# MLB0_VBP2APB_WRAP_MLB_CFG_VBP_MLBDIM register map
Vendor: Texas Instruments
Peripheral module from a debugger description file (folder J7ES).
Registers are 32-bit, read-write, reset 0x0 unless marked. A register's access mark holds for its fields unless they carry their own. Offsets are as the file gives them; lines under a group give offsets from that group; [hi:lo] are bit positions; {n}, {i} and the like mark numbered series; 'fields as' and 'values as' point back to an identical list; <NAME> marks a mode.

## MLB0_VBP2APB_WRAP_MLB_CFG_VBP_MLBDIM
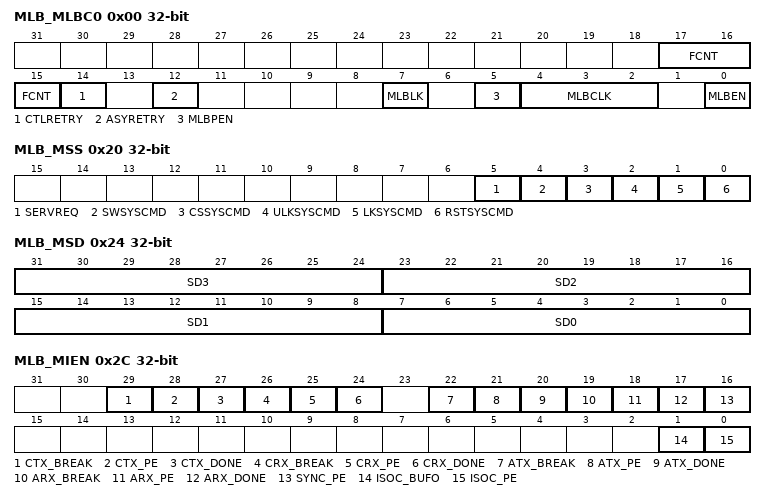
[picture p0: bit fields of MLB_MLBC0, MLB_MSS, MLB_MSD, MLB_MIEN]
0x00 MLB_MLBC0 access per field — MediaLB Control 0 Register.
  [17:15] FCNT rw — Number of frames per sub-buffer (synchronous channels).
  [14] CTLRETRY rw — Control Tx packet retry. When set, a control packet that is flagged with a Break or ProtocolError by the receiver is retransmitted. When cleared, a control packet that is flagged with a Break or ProtocolError by the receiver is skipped.
  [12] ASYRETRY rw — Asynchronous Tx packet retry. Asynchronous Tx packet retry. When set, an asynchronous packet that is flagged with a Break or ProtocolError by the receiver is retransmitted. When cleared, an asynchronous packet that is flagged with a Break or ProtocolError by the receiver is skipped.
  [7] MLBLK ro — MediaLB lock status. When set, indicates that the MediaLB block is synchronized to the incoming MediaLB frame. If MLBLK is clear (unlocked), MLBLK is set after FRAMESYNC is detected at the same position for three consecutive frames. If MLBLK is set (locked), MLBLK is cleared after not receiving FRAMESYNC at the expected time for two consecutive frames. While MLBLK is set, FRAMESYNC patterns occurring at locations other than the expected one are ignored. (read-only)
  [5] MLBPEN rw — MediaLB 6-pin enable.
  [4:2] MLBCLK rw — MediaLB clock speed select.
  [0] MLBEN rw — MediaLB enable. When set, MediaLB clock, signal, and data are received and transmitted on the appropriate MediaLB pins.
0x0C MLB_MS0 — MediaLB Channel Status 0 Register.
  [31:0] MCS_31_0 — MediaLB channel status (for channels 31 to 0). Channel status bits are set by hardware and cleared by software. Status is only set if the appropriate bits in the
0x14 MLB_MS1 — MediaLB Channel Status 1 Register.
  [31:0] MCS_63_32 — MediaLB channel status (for channels 63 to 32). Indicates the channel status for MediaLB channels 63 to 32. Channel status bits are set by hardware and cleared by software. Status is only set if the appropriate bits in the
0x20 MLB_MSS access per field — MediaLB System Status Register.
  [5] SERVREQ rw — Service request enabled. When set, the MediaLB block responds with a “device present, request service” system response if a matching channel scan system command is detected. When cleared, the MediaLB block responds with a “device present” system response.
  [4] SWSYSCMD rw — Software system command detected (in the system quadlet). Set by hardware, cleared by software. Data is stored in the
  [3] CSSYSCMD rw — Channel scan system command detected (in the system quadlet). Set by hardware, cleared by software. If the node address specified in Data quadlet matches the value in
  [2] ULKSYSCMD rw — Network unlock system command detected (in the system quadlet). Set by hardware, cleared by software. Writing a 1 has no effect.
  [1] LKSYSCMD rw — Network lock system command detected (in the system quadlet). Set by hardware, cleared by software. Writing a 1 has no effect.
  [0] RSTSYSCMD rw — Reset system command detected (in the system quadlet). Set by hardware, cleared by software. Writing a 1 has no effect.
0x24 MLB_MSD ro — MediaLB System Data Register.
  [31:24] SD3 — System data (byte 3). Updated with MediaLB Data[31-24] when a MediaLB software system command is received in the system quadlet. If
  [23:16] SD2 — System data (byte 2). Updated with MediaLB Data[23:16] when a MediaLB software system command is received in the system quadlet. If
  [15:8] SD1 — System data (byte 1). Updated with MediaLB Data[15:8] when a MediaLB software system command is received in the system quadlet. If
  [7:0] SD0 — System data (byte 0). Updated with MediaLB Data[7:0] when a MediaLB software system command is received in the system quadlet. If
0x2C MLB_MIEN — MediaLB Interrupt Enable Register.
  [29] CTX_BREAK — Control Tx break enable. When set, a ReceiverBreak response received from the receiver on a control Tx channel causes the appropriate channel bit in the
  [28] CTX_PE — Control Tx protocol error enable. When set, a ProtocolError generated by the receiver on a control Tx channel causes the appropriate channel bit in the
  [27] CTX_DONE — Control Tx packet done enable. When set, a packet transmitted with no errors on a control Tx channel causes the appropriate channel bit in the
  [26] CRX_BREAK — Control Rx break enable. When set, a ControlBreak command received from the transmitter on a control Rx channel causes the appropriate channel bit in the
  [25] CRX_PE — Control Rx protocol error enable. When set, a ProtocolError detected on a control Rx channel causes the appropriate channel bit in the
  [24] CRX_DONE — Control Rx packet done enable. When set, a packet received with no errors on a control Rx channel causes the appropriate channel bit in the
  [22] ATX_BREAK — Asynchronous Tx break enable. When set, a ReceiverBreak response received from the receiver on an asynchronous Tx channel causes the appropriate channel bit in the
  [21] ATX_PE — Asynchronous Tx protocol error enable. When set, a ProtocolError generated by the receiver on an asynchronous Tx channel causes the appropriate channel bit in the
  [20] ATX_DONE — Asynchronous Tx packet done enable. When set, a packet transmitted with no errors on an asynchronous Tx channel causes the appropriate channel bit in the
  [19] ARX_BREAK — Asynchronous Rx break enable. When set, a AsyncBreak command received from the transmitter on an asynchronous Rx channel causes the appropriate channel bit in the
  [18] ARX_PE — Asynchronous Rx protocol error enable. When set, a ProtocolError detected on an asynchronous Rx channel causes the appropriate channel bit in the
  [17] ARX_DONE — Asynchronous Rx done enable. When set, a packet received with no errors on an asynchronous Rx channel causes the appropriate channel bit in the
  [16] SYNC_PE — Synchronous protocol error enable. When set, a ProtocolError detected on a synchronous Rx channel causes the appropriate channel bit in the
  [1] ISOC_BUFO — Isochronous Rx buffer overflow enable. When set, a buffer overflow on an isochronous Rx channel causes the appropriate channel bit in the
  [0] ISOC_PE — Isochronous Rx protocol error enable. When set, a ProtocolError detected on an isochronous Rx channel causes the appropriate channel bit in the
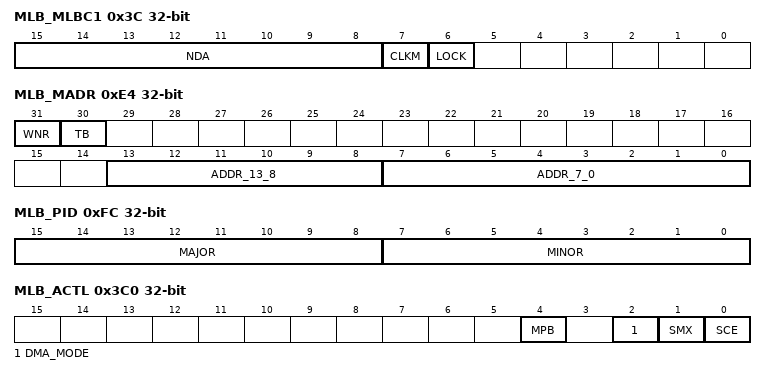
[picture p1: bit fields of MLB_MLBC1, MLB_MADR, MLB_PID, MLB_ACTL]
0x3C MLB_MLBC1 access per field — MediaLB Control 1 Register.
  [15:8] NDA rw — Node device address. Used for system commands directed to individual MediaLB nodes.
  [7] CLKM rw — MediaLB clock missing status. Set when MediaLB clock is not toggling at the pin; cleared by software. Writing a 1 has no effect.
  [6] LOCK rw — MediaLB lock error status. Set when MediaLB is unlocked; cleared by software. Writing a 1 has no effect.
0x80 MLB_HCTL — HBI Control Register.
  [15] EN — HBI enable:
0x88 MLB_HCMR0 — HBI Channel Mask 0 Register.
  [31:0] CHM_31_0 — Bitwise channel mask bit:
0x8C MLB_HCMR1 — HBI Channel Mask 1 Register.
  [31:0] CHM_63_32 — Bitwise channel mask bit:
0x90 MLB_HCER0 — HBI Channel Error 0 Register.
  [31:0] CERR_31_0 — Bitwise channel error bit. Writing a 1 has no effect.
0x94 MLB_HCER1 — HBI Channel Error 1 Register.
  [31:0] CERR_63_32 — Bitwise channel error bit. Writing a 1 has no effect.
0x98 MLB_HCBR0 ro — HBI Channel Busy 0 Register.
  [31:0] CHB_31_0 — Bitwise channel busy bit:
0x9C MLB_HCBR1 ro — HBI Channel Busy 1 Register.
  [31:0] CHB_63_32 — Bitwise channel busy bit:
0xC0 MLB_MDAT0 — Memory Interface Data 0 Register.
  [31:0] DATA_31_0 — CTR data - bits[31-0] of 128-bit entry or
{0xC0+4i} MLB_MDAT{i} (i=1..3) — Memory Interface Data {i} Register.
  [31:0] DATA_{32i+31}_{32i} — CTR data - bits[{32i+31}-{32i}] of 128-bit entry
{0xD0+4i} MLB_MDWE{i} (i=0..3) — Memory Interface Data Write Enable {i} Register.
  [31:0] MASK_{32i+31}_{32i} — Bitwise write enable for CTR data - bits[{32i+31}-{32i}] (0 = disabled, 1 = enabled)
0xE0 MLB_MCTL — Memory Interface Control Register.
  [0] XCMP — Transfer complete (write 0 to clear). Writing a 1 has no effect.
0xE4 MLB_MADR — Memory Interface Address Register.
  [31] WNR — Write-Not-Read selection (0 = read, 1 = write)
  [30] TB — Target location bit (0 = selects CTR, 1 = selects DBR)
  [13:8] ADDR_13_8 — DBR address of 8-bit entry - bits[13-8]
  [7:0] ADDR_7_0 — CTR address of 128-bit entry or DBR address of 8-bit entry - bits[7-0]
0xFC MLB_PID ro (reset mask 0xFFFF0000) — MediaLB Core Revision Register.
  [15:8] MAJOR — Major revision
  [7:0] MINOR — Minor revision
0x3C0 MLB_ACTL — AHB Control Register.
  [4] MPB — Packet buffering mode:
  [2] DMA_MODE
  [1] SMX — AHB interrupt mux enable:
  [0] SCE — Software clear enable:
0x3D0 MLB_ACSR0 access not given — AHB Channel Status 0 Register.
  [31:0] CHS_31_0 — Interrupt status for logical channels 31 to 0: (access RW1toCl)
0x3D4 MLB_ACSR1 access not given — AHB Channel Status 1 Register.
  [31:0] CHS_63_32 — Interrupt status for logical channels 32 to 63: (access RW1toCl)
0x3D8 MLB_ACMR0 — AHB Channel Mask 0 Register.
  [31:0] CHM_31_0 — Bitwise channel mask bit:
0x3DC MLB_ACMR1 — AHB Channel Mask 1 Register.
  [31:0] CHM_63_32 — Bitwise channel mask bit:
